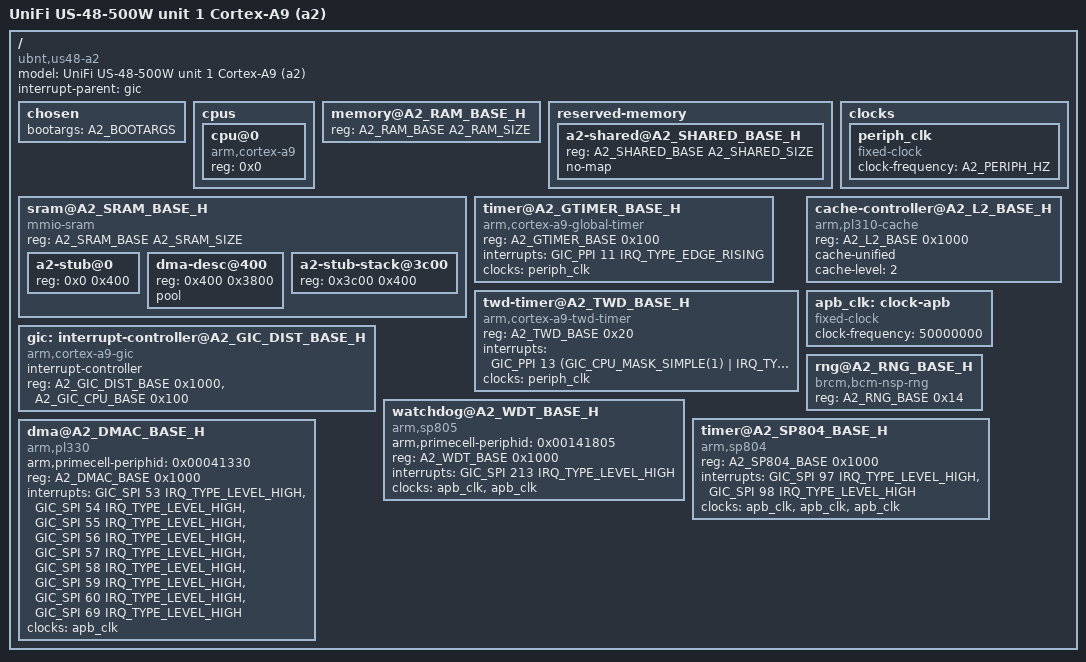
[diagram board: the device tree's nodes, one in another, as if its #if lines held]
// SPDX-License-Identifier: GPL-2.0-or-later OR MIT
/*
 * a2: Cortex-A9 inside the BCM53346 (unit 1) of the US-48-500W, Linux in AMP next to a1.
 * Same kernel image as a1; only this DTB (r2, nothing appended) and its bootargs differ.
 * Addresses come from hwdb via scripts/build_a2_linux.py (-D macros): never edited here.
 * Deliberately absent (a2 must not touch): DDR controller 0x60000000 (stalls a2), QSPI/flash, PCIe,
 * L2 PL310 (left off as the boot ROM leaves it), anything on the CCB/APB buses (docs/a2.md, #53).
 * Clock: PERIPHCLK = ARM/2 (docs/a2-linux.md).
 */

/dts-v1/;

#include <dt-bindings/interrupt-controller/arm-gic.h>
#include <dt-bindings/interrupt-controller/irq.h>

#if !defined(A2_RAM_BASE) || !defined(A2_RAM_SIZE) || !defined(A2_SHARED_BASE) || !defined(A2_SHARED_SIZE) || !defined(A2_SRAM_BASE) || !defined(A2_SRAM_SIZE) || \
	!defined(A2_GIC_DIST_BASE_H) || !defined(A2_GIC_DIST_BASE) || !defined(A2_GIC_CPU_BASE) || !defined(A2_GTIMER_BASE) || !defined(A2_TWD_BASE) || !defined(A2_PERIPH_HZ) || !defined(A2_BOOTARGS)
#error "A2_* macros (value and _H unit-address digits) come from hwdb via scripts/build_a2_linux.py"
#endif

/* Unit 1 CCB/APB test peripherals (#84): off unless build_a2_linux.py --periph / --dmac says "okay" */
#ifndef A2_PERIPH_STATUS
#define A2_PERIPH_STATUS "disabled"
#endif
#ifndef A2_DMAC_STATUS
#define A2_DMAC_STATUS "disabled"
#endif

/ {
	compatible = "ubnt,us48-a2", "brcm,hr2";
	model = "UniFi US-48-500W unit 1 Cortex-A9 (a2)";
	interrupt-parent = <&gic>;
	#address-cells = <1>;
	#size-cells = <1>;

	chosen {
		/* DCC console: a1 drains DBGDTRTX over PCIe (docs/a2-linux.md). No ttyS: unit 1 UART is not wired. */
		bootargs = A2_BOOTARGS;
	};

	cpus {
		#address-cells = <1>;
		#size-cells = <0>;

		cpu@0 {
			device_type = "cpu";
			compatible = "arm,cortex-a9";
			reg = <0x0>;
		};
	};

	/* a2 view of host DDR through PAXB OARR_0/OMAP_0; the last MiB is rproc shared state, not Linux RAM */
	memory@A2_RAM_BASE_H {
		device_type = "memory";
		reg = <A2_RAM_BASE A2_RAM_SIZE>;
	};

	reserved-memory {
		#address-cells = <1>;
		#size-cells = <1>;
		ranges;

		/* resource table, trace ring, vrings: written by a1 (remoteproc), never mapped by Linux */
		a2-shared@A2_SHARED_BASE_H {
			reg = <A2_SHARED_BASE A2_SHARED_SIZE>;
			no-map;
		};
	};

	/*
	 * Unit 1 on-chip SRAM (hwdb a2_sram, size conf I like unit 0). The two stub partitions are the bring-up
	 * layout of tools/a2_stub.S (docs/a2.md: mailbox +0x100, payload +0x200, stack top +0x3ff0); not pool,
	 * so nothing allocates over them. The rest is a pool for DMA descriptors.
	 */
	sram@A2_SRAM_BASE_H {
		compatible = "mmio-sram";
		reg = <A2_SRAM_BASE A2_SRAM_SIZE>;
		#address-cells = <1>;
		#size-cells = <1>;
		ranges = <0 A2_SRAM_BASE A2_SRAM_SIZE>;

		a2-stub@0 {
			reg = <0x0 0x400>;
		};

		dma-desc@400 {
			reg = <0x400 0x3800>;
			pool;
		};

		a2-stub-stack@3c00 {
			reg = <0x3c00 0x400>;
		};
	};

	clocks {
		/* PERIPHCLK = ARM/2 (conf I, host-timed on unit 1); ARM = us48_a2 cpu_mhz, A2_PERIPH_HZ from build_a2_linux.py --cpu-mhz */
		periph_clk: periph_clk {
			#clock-cells = <0>;
			compatible = "fixed-clock";
			clock-frequency = <A2_PERIPH_HZ>;
		};
	};

	timer@A2_GTIMER_BASE_H {
		compatible = "arm,cortex-a9-global-timer";
		reg = <A2_GTIMER_BASE 0x100>;
		interrupts = <GIC_PPI 11 IRQ_TYPE_EDGE_RISING>;
		clocks = <&periph_clk>;
	};

	twd-timer@A2_TWD_BASE_H {
		compatible = "arm,cortex-a9-twd-timer";
		reg = <A2_TWD_BASE 0x20>;
		interrupts = <GIC_PPI 13 (GIC_CPU_MASK_SIMPLE(1) | IRQ_TYPE_EDGE_RISING)>;
		clocks = <&periph_clk>;
	};

#ifdef A2_L2
	/* PL310 of unit 1 (hwdb a9 l2 block at +0x2000): enabled by the kernel from this node, off otherwise (#79) */
	cache-controller@A2_L2_BASE_H {
		compatible = "arm,pl310-cache";
		reg = <A2_L2_BASE 0x1000>;
		cache-unified;
		cache-level = <2>;
	};
#endif

	gic: interrupt-controller@A2_GIC_DIST_BASE_H {
		compatible = "arm,cortex-a9-gic";
		#interrupt-cells = <3>;
		#address-cells = <0>;
		interrupt-controller;
		reg = <A2_GIC_DIST_BASE 0x1000>, <A2_GIC_CPU_BASE 0x100>;
	};

	/*
	 * Unit 1 CCB/APB blocks (#84), conf I: same die as unit 0, so addresses (hwdb), IRQs (bcm-hr2.dtsi) and the
	 * 50 MHz APB clock are taken as equal; none of it is measured on unit 1. Fixed PERIPIDs: no ID read at boot.
	 */
	apb_clk: clock-apb {
		#clock-cells = <0>;
		compatible = "fixed-clock";
		clock-frequency = <50000000>;
	};

	rng@A2_RNG_BASE_H {
		compatible = "brcm,bcm-nsp-rng";
		reg = <A2_RNG_BASE 0x14>;
		status = A2_PERIPH_STATUS;
	};

	watchdog@A2_WDT_BASE_H {
		compatible = "arm,sp805", "arm,primecell";
		arm,primecell-periphid = <0x00141805>;
		reg = <A2_WDT_BASE 0x1000>;
		interrupts = <GIC_SPI 213 IRQ_TYPE_LEVEL_HIGH>;
		clocks = <&apb_clk>, <&apb_clk>;
		clock-names = "wdog_clk", "apb_pclk";
		status = A2_PERIPH_STATUS;
	};

	timer@A2_SP804_BASE_H {
		compatible = "arm,sp804";
		reg = <A2_SP804_BASE 0x1000>;
		interrupts = <GIC_SPI 97 IRQ_TYPE_LEVEL_HIGH>, <GIC_SPI 98 IRQ_TYPE_LEVEL_HIGH>;
		clocks = <&apb_clk>, <&apb_clk>, <&apb_clk>;
		clock-names = "timer0clk", "timer1clk", "apb_pclk";
		status = A2_PERIPH_STATUS;
	};

	/* stalls the bus while dmac_idm.RESET_CONTROL is 1 (hwdb): a2 cannot release it itself, a1 does it over PCIe */
	dma@A2_DMAC_BASE_H {
		compatible = "arm,pl330", "arm,primecell";
		arm,primecell-periphid = <0x00041330>;
		reg = <A2_DMAC_BASE 0x1000>;
		interrupts = <GIC_SPI 53 IRQ_TYPE_LEVEL_HIGH>, <GIC_SPI 54 IRQ_TYPE_LEVEL_HIGH>,
			     <GIC_SPI 55 IRQ_TYPE_LEVEL_HIGH>, <GIC_SPI 56 IRQ_TYPE_LEVEL_HIGH>,
			     <GIC_SPI 57 IRQ_TYPE_LEVEL_HIGH>, <GIC_SPI 58 IRQ_TYPE_LEVEL_HIGH>,
			     <GIC_SPI 59 IRQ_TYPE_LEVEL_HIGH>, <GIC_SPI 60 IRQ_TYPE_LEVEL_HIGH>,
			     <GIC_SPI 69 IRQ_TYPE_LEVEL_HIGH>;
		clocks = <&apb_clk>;
		clock-names = "apb_pclk";
		#dma-cells = <1>;
		status = A2_DMAC_STATUS;
	};
};
